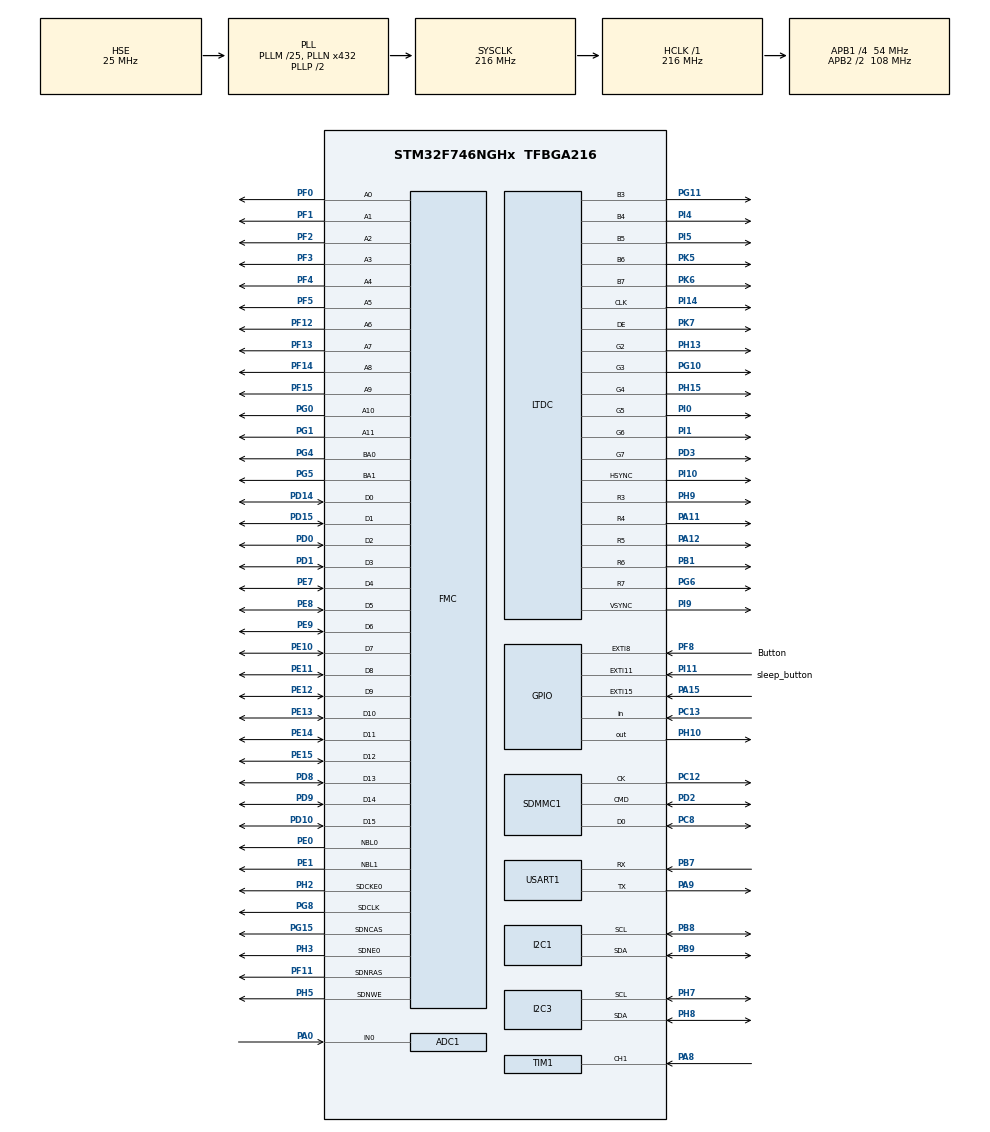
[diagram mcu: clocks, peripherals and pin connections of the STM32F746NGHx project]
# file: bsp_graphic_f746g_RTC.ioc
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ADC1.Channel-0\#ChannelRegularConversion=ADC_CHANNEL_0
ADC1.NbrOfConversionFlag=1
ADC1.Rank-0\#ChannelRegularConversion=1
ADC1.SamplingTime-0\#ChannelRegularConversion=ADC_SAMPLETIME_3CYCLES
ADC1.master=1
CORTEX_M7.ART_ACCELERATOR_ENABLE=1
Dma.Request0=SDMMC1_RX
Dma.Request1=SDMMC1_TX
Dma.SDMMC1_RX.0.Direction=DMA_PERIPH_TO_MEMORY
Dma.SDMMC1_RX.0.FIFOMode=DMA_FIFOMODE_ENABLE
Dma.SDMMC1_RX.0.FIFOThreshold=DMA_FIFO_THRESHOLD_FULL
Dma.SDMMC1_RX.0.Instance=DMA2_Stream3
Dma.SDMMC1_RX.0.MemBurst=DMA_MBURST_INC4
Dma.SDMMC1_RX.0.MemDataAlignment=DMA_MDATAALIGN_WORD
Dma.SDMMC1_RX.0.MemInc=DMA_MINC_ENABLE
Dma.SDMMC1_RX.0.Mode=DMA_PFCTRL
Dma.SDMMC1_RX.0.PeriphBurst=DMA_PBURST_INC4
Dma.SDMMC1_RX.0.PeriphDataAlignment=DMA_PDATAALIGN_WORD
Dma.SDMMC1_RX.0.PeriphInc=DMA_PINC_DISABLE
Dma.SDMMC1_RX.0.Priority=DMA_PRIORITY_LOW
Dma.SDMMC1_TX.1.Direction=DMA_MEMORY_TO_PERIPH
Dma.SDMMC1_TX.1.FIFOMode=DMA_FIFOMODE_ENABLE
Dma.SDMMC1_TX.1.FIFOThreshold=DMA_FIFO_THRESHOLD_FULL
Dma.SDMMC1_TX.1.Instance=DMA2_Stream6
Dma.SDMMC1_TX.1.MemBurst=DMA_MBURST_INC4
Dma.SDMMC1_TX.1.MemDataAlignment=DMA_MDATAALIGN_WORD
Dma.SDMMC1_TX.1.MemInc=DMA_MINC_ENABLE
Dma.SDMMC1_TX.1.Mode=DMA_PFCTRL
Dma.SDMMC1_TX.1.PeriphBurst=DMA_PBURST_INC4
Dma.SDMMC1_TX.1.PeriphDataAlignment=DMA_PDATAALIGN_WORD
Dma.SDMMC1_TX.1.PeriphInc=DMA_PINC_DISABLE
Dma.SDMMC1_TX.1.Priority=DMA_PRIORITY_LOW
FATFS.BSP.number=1
FATFS.USE_DMA_CODE_SD=1
FATFS0.BSP.STBoard=false
FATFS0.BSP.api=Unknown
FATFS0.BSP.instance=PC13
FATFS0.BSP.ip=GPIO
FATFS0.BSP.mode=Input
FATFS0.BSP.name=Detect_SDIO
FATFS0.BSP.solution=PC13
I2C1.Timing=0x20404768
I2C3.Timing=0x20404768
LTDC.ActiveH=272
LTDC.ActiveW=480
LTDC.Alpha_L0=255
LTDC.BlendingFactor1_L0=LTDC_BLENDING_FACTOR1_PAxCA
LTDC.BlendingFactor2_L0=LTDC_BLENDING_FACTOR2_PAxCA
LTDC.HBP=43
LTDC.HFP=8
LTDC.HSync=1
LTDC.ImageHeight_L0=272
LTDC.ImageWidth_L0=480
LTDC.Layers=0
LTDC.PixelFormat_L0=LTDC_PIXEL_FORMAT_RGB565
LTDC.VBP=12
LTDC.VFP=4
LTDC.VSync=10
LTDC.WindowX1_L0=480
LTDC.WindowY1_L0=272
Mcu.Family=STM32F7
Mcu.Name=STM32F746NGHx
Mcu.Package=TFBGA216
NVIC.DMA2_Stream3_IRQn=true\:0\:0\:false\:false\:true\:false\:true\:true
NVIC.DMA2_Stream6_IRQn=true\:0\:0\:false\:false\:true\:false\:true\:true
NVIC.EXTI15_10_IRQn=true\:2\:0\:true\:false\:true\:true\:true\:true
NVIC.EXTI9_5_IRQn=true\:0\:0\:false\:false\:true\:true\:true\:true
NVIC.PriorityGroup=NVIC_PRIORITYGROUP_4
NVIC.RTC_WKUP_IRQn=true\:0\:0\:false\:false\:true\:true\:true\:true
NVIC.SDMMC1_IRQn=true\:0\:0\:false\:false\:true\:true\:true\:true
NVIC.TIM1_CC_IRQn=true\:0\:0\:false\:false\:true\:true\:true\:true
NVIC.TIM2_IRQn=true\:0\:0\:false\:false\:true\:true\:true\:true
NVIC.TIM3_IRQn=true\:0\:0\:false\:false\:true\:true\:true\:true
NVIC.TIM5_IRQn=true\:1\:0\:true\:false\:true\:true\:true\:true
NVIC.TIM6_DAC_IRQn=true\:3\:0\:true\:false\:true\:true\:true\:true
NVIC.TIM7_IRQn=true\:4\:0\:true\:false\:true\:true\:true\:true
NVIC.TIM8_BRK_TIM12_IRQn=true\:0\:0\:false\:false\:true\:true\:true\:true
NVIC.TIM8_UP_TIM13_IRQn=true\:0\:0\:false\:false\:true\:true\:true\:true
PA0/WKUP.Signal=ADCx_IN0
PA11.Mode=RGB565
PA11.Signal=LTDC_R4
PA12.Mode=RGB565
PA12.Signal=LTDC_R5
PA13.Mode=Serial_Wire
PA13.Signal=SYS_JTMS-SWDIO
PA14.Mode=Serial_Wire
PA14.Signal=SYS_JTCK-SWCLK
PA15.GPIO_PuPd=GPIO_PULLUP
PA15.Signal=GPXTI15
PA7.Signal=TIM1_CH1N
PA8.GPIO_PuPd=GPIO_PULLUP
PA8.Signal=S_TIM1_CH1
PA9.Mode=Asynchronous
PA9.Signal=USART1_TX
PB1.Mode=RGB565
PB1.Signal=LTDC_R6
PB7.Mode=Asynchronous
PB7.Signal=USART1_RX
PB8.Mode=I2C
PB8.Signal=I2C1_SCL
PB9.Mode=I2C
PB9.Signal=I2C1_SDA
PC12.Mode=SD_1_bit
PC12.Signal=SDMMC1_CK
PC13.Signal=GPIO_Input
PC14/OSC32_IN.Mode=LSE-External-Oscillator
PC14/OSC32_IN.Signal=RCC_OSC32_IN
PC15/OSC32_OUT.Mode=LSE-External-Oscillator
PC15/OSC32_OUT.Signal=RCC_OSC32_OUT
PC8.Mode=SD_1_bit
PC8.Signal=SDMMC1_D0
PD0.Signal=FMC_D2_DA2
PD1.Signal=FMC_D3_DA3
PD10.Signal=FMC_D15_DA15
PD14.Signal=FMC_D0_DA0
PD15.Signal=FMC_D1_DA1
PD2.Mode=SD_1_bit
PD2.Signal=SDMMC1_CMD
PD3.Mode=RGB565
PD3.Signal=LTDC_G7
PD8.Signal=FMC_D13_DA13
PD9.Signal=FMC_D14_DA14
PE0.Signal=FMC_NBL0
PE1.Signal=FMC_NBL1
PE10.Signal=FMC_D7_DA7
PE11.Signal=FMC_D8_DA8
PE12.Signal=FMC_D9_DA9
PE13.Signal=FMC_D10_DA10
PE14.Signal=FMC_D11_DA11
PE15.Signal=FMC_D12_DA12
PE7.Signal=FMC_D4_DA4
PE8.Signal=FMC_D5_DA5
PE9.Signal=FMC_D6_DA6
PF0.Signal=FMC_A0
PF1.Signal=FMC_A1
PF11.Signal=FMC_SDNRAS
PF12.Signal=FMC_A6
PF13.Signal=FMC_A7
PF14.Signal=FMC_A8
PF15.Signal=FMC_A9
PF2.Signal=FMC_A2
PF3.Signal=FMC_A3
PF4.Signal=FMC_A4
PF5.Signal=FMC_A5
PF8.GPIO_Label=Button
PF8.Signal=GPXTI8
PG0.Signal=FMC_A10
PG1.Signal=FMC_A11
PG10.Mode=RGB565
PG10.Signal=LTDC_G3
PG11.Mode=RGB565
PG11.Signal=LTDC_B3
PG15.Signal=FMC_SDNCAS
PG4.Signal=FMC_A14_BA0
PG5.Signal=FMC_A15_BA1
PG6.Mode=RGB565
PG6.Signal=LTDC_R7
PG8.Signal=FMC_SDCLK
PH0/OSC_IN.Mode=HSE-External-Oscillator
PH0/OSC_IN.Signal=RCC_OSC_IN
PH1/OSC_OUT.Mode=HSE-External-Oscillator
PH1/OSC_OUT.Signal=RCC_OSC_OUT
PH10.Signal=GPIO_Output
PH13.Mode=RGB565
PH13.Signal=LTDC_G2
PH15.Mode=RGB565
PH15.Signal=LTDC_G4
PH2.Mode=SdramChipSelect1_1
PH2.Signal=FMC_SDCKE0
PH3.Mode=SdramChipSelect1_1
PH3.Signal=FMC_SDNE0
PH5.Signal=FMC_SDNWE
PH7.Mode=I2C
PH7.Signal=I2C3_SCL
PH8.Mode=I2C
PH8.Signal=I2C3_SDA
PH9.Mode=RGB565
PH9.Signal=LTDC_R3
PI0.Mode=RGB565
PI0.Signal=LTDC_G5
PI1.Mode=RGB565
PI1.Signal=LTDC_G6
PI10.Mode=RGB565
PI10.Signal=LTDC_HSYNC
PI11.GPIO_Label=sleep_button
PI11.Signal=GPXTI11
PI14.Mode=RGB565
PI14.Signal=LTDC_CLK
PI4.Mode=RGB565
PI4.Signal=LTDC_B4
PI5.Mode=RGB565
PI5.Signal=LTDC_B5
PI9.Mode=RGB565
PI9.Signal=LTDC_VSYNC
PK5.Mode=RGB565
PK5.Signal=LTDC_B6
PK6.Mode=RGB565
PK6.Signal=LTDC_B7
PK7.Mode=RGB565
PK7.Signal=LTDC_DE
ProjectManager.HeapSize=0x400
ProjectManager.StackSize=0x800
ProjectManager.TargetToolchain=STM32CubeIDE
RCC.AHBFreq_Value=216000000
RCC.APB1CLKDivider=RCC_HCLK_DIV4
RCC.APB1Freq_Value=54000000
RCC.APB1TimFreq_Value=108000000
RCC.APB2CLKDivider=RCC_HCLK_DIV2
RCC.APB2Freq_Value=108000000
RCC.APB2TimFreq_Value=216000000
RCC.CortexFreq_Value=216000000
RCC.HCLKFreq_Value=216000000
RCC.HSE_VALUE=25000000
RCC.HSI_VALUE=16000000
RCC.PLLM=25
RCC.PLLN=432
RCC.PLLQ=9
RCC.PLLSAIN=100
RCC.PLLSAIR=4
RCC.PLLSAIRDiv=RCC_PLLSAIDIVR_4
RCC.PLLSourceVirtual=RCC_PLLSOURCE_HSE
RCC.SDMMCClockSelection=RCC_SDMMC1CLKSOURCE_CLK48
RCC.SYSCLKFreq_VALUE=216000000
RCC.SYSCLKSource=RCC_SYSCLKSOURCE_PLLCLK
RCC.USBFreq_Value=48000000
RCC.VCOOutputFreq_Value=432000000
RTC.Alarm-Alarm\ A=RTC_ALARM_A
RTC.Format=RTC_FORMAT_BIN
SH.ADCx_IN0.0=ADC1_IN0,IN0
SH.FMC_A0.0=FMC_A0,12b-sda1
SH.FMC_A1.0=FMC_A1,12b-sda1
SH.FMC_A10.0=FMC_A10,12b-sda1
SH.FMC_A11.0=FMC_A11,12b-sda1
SH.FMC_A14_BA0.0=FMC_BA0,FourSdramBanks1
SH.FMC_A15_BA1.0=FMC_BA1,FourSdramBanks1
SH.FMC_A2.0=FMC_A2,12b-sda1
SH.FMC_A3.0=FMC_A3,12b-sda1
SH.FMC_A4.0=FMC_A4,12b-sda1
SH.FMC_A5.0=FMC_A5,12b-sda1
SH.FMC_A6.0=FMC_A6,12b-sda1
SH.FMC_A7.0=FMC_A7,12b-sda1
SH.FMC_A8.0=FMC_A8,12b-sda1
SH.FMC_A9.0=FMC_A9,12b-sda1
SH.FMC_D0_DA0.0=FMC_D0,sd-16b-d1
SH.FMC_D10_DA10.0=FMC_D10,sd-16b-d1
SH.FMC_D11_DA11.0=FMC_D11,sd-16b-d1
SH.FMC_D12_DA12.0=FMC_D12,sd-16b-d1
SH.FMC_D13_DA13.0=FMC_D13,sd-16b-d1
SH.FMC_D14_DA14.0=FMC_D14,sd-16b-d1
SH.FMC_D15_DA15.0=FMC_D15,sd-16b-d1
SH.FMC_D1_DA1.0=FMC_D1,sd-16b-d1
SH.FMC_D2_DA2.0=FMC_D2,sd-16b-d1
SH.FMC_D3_DA3.0=FMC_D3,sd-16b-d1
SH.FMC_D4_DA4.0=FMC_D4,sd-16b-d1
SH.FMC_D5_DA5.0=FMC_D5,sd-16b-d1
SH.FMC_D6_DA6.0=FMC_D6,sd-16b-d1
SH.FMC_D7_DA7.0=FMC_D7,sd-16b-d1
SH.FMC_D8_DA8.0=FMC_D8,sd-16b-d1
SH.FMC_D9_DA9.0=FMC_D9,sd-16b-d1
SH.FMC_NBL0.0=FMC_NBL0,Sd2ByteEnable1
SH.FMC_NBL1.0=FMC_NBL1,Sd2ByteEnable1
SH.FMC_SDCLK.0=FMC_SDCLK,12b-sda1
SH.FMC_SDNCAS.0=FMC_SDNCAS,12b-sda1
SH.FMC_SDNRAS.0=FMC_SDNRAS,12b-sda1
SH.FMC_SDNWE.0=FMC_SDNWE,12b-sda1
SH.S_TIM1_CH1.0=TIM1_CH1,Input_Capture1_from_TI1
TIM1.Channel-Input_Capture1_from_TI1=TIM_CHANNEL_1
TIM1.Prescaler=99
TIM2.Period=599999
TIM2.Prescaler=10799
TIM3.Period=199
TIM3.Prescaler=9999
TIM5.Period=299999
TIM5.Prescaler=10799
TIM6.Period=8232
TIM6.Prescaler=65535
TIM7.Period=65535
TIM7.Prescaler=3294
TIM8.Prescaler=8231
USART1.VirtualMode-Asynchronous=VM_ASYNC
VP_DMA2D_VS_DMA2D.Mode=DMA2D_Activate
VP_FATFS_VS_SDIO.Mode=SDIO
VP_RTC_VS_RTC_Activate.Mode=RTC_Enabled
VP_RTC_VS_RTC_Alarm_A_Intern.Mode=Alarm A
VP_RTC_VS_RTC_Calendar.Mode=RTC_Calendar
VP_RTC_VS_RTC_WakeUp_intern.Mode=WakeUp
VP_TIM2_VS_ClockSourceITR.Mode=TriggerSource_ITR0
VP_TIM2_VS_ControllerModeReset.Mode=Reset Mode
VP_TIM3_VS_ClockSourceITR.Mode=TriggerSource_ITR0
VP_TIM3_VS_ControllerModeReset.Mode=Reset Mode
VP_TIM5_VS_ClockSourceITR.Mode=TriggerSource_ITR0
VP_TIM5_VS_ControllerModeReset.Mode=Reset Mode
VP_TIM6_VS_ClockSourceINT.Mode=Enable_Timer
VP_TIM7_VS_ClockSourceINT.Mode=Enable_Timer
VP_TIM8_VS_ClockSourceITR.Mode=TriggerSource_ITR0
VP_TIM8_VS_ControllerModeReset.Mode=Reset Mode
board=STM32F746G-DISCO

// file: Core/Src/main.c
/* USER CODE BEGIN Header */
/**
  ******************************************************************************
  * @file           : main.c
  * @brief          : Main program body
  ******************************************************************************
  * @attention
  *
  * Copyright (c) 2023 STMicroelectronics.
  * All rights reserved.
  *
  * This software is licensed under terms that can be found in the LICENSE file
  * in the root directory of this software component.
  * If no LICENSE file comes with this software, it is provided AS-IS.
  *
  ******************************************************************************
  */
/* USER CODE END Header */
#include "main.h"
#include "adc.h"
#include "dma.h"
#include "dma2d.h"
#include "fatfs.h"
#include "i2c.h"
#include "ltdc.h"
#include "rtc.h"
#include "sdmmc.h"
#include "tim.h"
#include "usart.h"
#include "gpio.h"
#include "fmc.h"

/* USER CODE BEGIN Includes */
#include "stdio.h"
#include <string.h>
#include "stm32746g_discovery.h"
#include "stm32746g_discovery_sdram.h"
#include "stm32746g_discovery_lcd.h"
#include "stm32746g_discovery_ts.h"

#include "Interface.h"
#include "Nucleo_HumTemp_I2C.h"
#include "Nucleo_Pression_I2C.h"
#include "Rain_Measure_Sparkfun.h"
#include "SD_card.h"
#include "Wind_Dir_Sparkfun.h"
#include "Wind_Speed_Sparkfun.h"
/*#include "Rain_Measure_Sparkfun.h"
#include "Wind_Dir_Sparkfun.h"
#include "Wind_Speed_Sparkfun.h"
*/
/* USER CODE END Includes */

/* USER CODE BEGIN PV */

//Taille de l'écran

volatile TS_StateTypeDef  TS_State;
volatile uint16_t x, y;
int needRedraw=1;
int debounce = 0; // Debounce flag

// Variable pour suivre l'état du système
extern uint8_t minute_flag;  // Flag pour indiquer que 1 minute est écoulée
uint8_t flag=0;
volatile uint8_t flag_meteo=0;
extern int graph_open_flag;

uint8_t flag_ext_button=0;
uint8_t time_IRQ_acquisition;
uint8_t flag_IRQ_sleep=0;

extern uint32_t rainCount;
extern uint8_t flagRain;

/* USER CODE END PV */

void SystemClock_Config(void);
/* USER CODE BEGIN PFP */

#ifdef __GNUC__
/* With GCC/RAISONANCE, small printf (option LD Linker->Libraries->Small printf
set to 'Yes') calls __io_putchar() */
#define PUTCHAR_PROTOTYPE int __io_putchar(int ch)
#else
#define PUTCHAR_PROTOTYPE int fputc(int ch, FILE *f)
#endif /* __GNUC__ */

void TouchTimer_Init(void);

/**
 * @brief Récupère la date formatée depuis la RTC
 * @param dateStr: buffer pour stocker la chaîne formatée
 */
void getRTCDateStr(char* dateStr) {
    // Lecture de l'heure (nécessaire avant la date)
    HAL_RTC_GetTime(&hrtc, &sTime, RTC_FORMAT_BIN);
    // Lecture de la date
    HAL_RTC_GetDate(&hrtc, &sDate, RTC_FORMAT_BIN);

    // Format: "Jour JJ/MM/AAAA"
    sprintf(dateStr, "%02d/%02d/20%02d",
            sDate.Date,
            sDate.Month,
            sDate.Year);
}

/**
 * @brief Récupère l'heure formatée depuis la RTC
 * @param timeStr: buffer pour stocker la chaîne formatée
 */

/* USER CODE END PFP */

int main(void)
{

  /* MCU Configuration--------------------------------------------------------*/

  /* Reset of all peripherals, Initializes the Flash interface and the Systick. */
  HAL_Init();

  /* Configure the system clock */
  SystemClock_Config();

  /* Initialize all configured peripherals */
  MX_GPIO_Init();
  MX_DMA_Init();
  MX_DMA2D_Init();
  MX_FMC_Init();
  MX_LTDC_Init();
  MX_USART1_UART_Init();
  MX_I2C3_Init();
  MX_TIM3_Init();
  MX_RTC_Init();
  MX_SDMMC1_SD_Init();
  MX_I2C1_Init();
  MX_FATFS_Init();
  MX_ADC1_Init();
  MX_TIM1_Init();
  MX_TIM6_Init();
  MX_TIM7_Init();
  MX_TIM5_Init();
  MX_TIM8_Init();
  MX_TIM2_Init();
  /* USER CODE BEGIN 2 */
  BSP_LCD_Init();
  BSP_LCD_LayerDefaultInit(LTDC_ACTIVE_LAYER, SDRAM_DEVICE_ADDR);
  BSP_LCD_SetLayerVisible(LTDC_ACTIVE_LAYER, ENABLE);
  BSP_LCD_SetFont(&LCD_DEFAULT_FONT);
  BSP_LCD_SelectLayer(LTDC_ACTIVE_LAYER);
  BSP_LCD_Clear(LCD_COLOR_WHITE);
  BSP_LCD_SetBackColor(LCD_COLOR_WHITE);
  BSP_LCD_SetTextColor(LCD_COLOR_BLACK);

  init_HumTemp();
  init_Pression();
  //BSP_TS_Init(BSP_LCD_GetXSize(), BSP_LCD_GetYSize());
  TouchTimer_Init();
  HAL_TIM_IC_Start_IT(&htim1, TIM_CHANNEL_1);
  HAL_TIM_Base_Start_IT(&htim7);

  __HAL_TIM_SET_COUNTER(&htim5, 0);           // Réinitialise le compteur à 0
  __HAL_TIM_CLEAR_FLAG(&htim5, TIM_FLAG_UPDATE); // Efface le drapeau d'interruption
  HAL_TIM_Base_Start_IT(&htim5);

  __HAL_TIM_SET_COUNTER(&htim8, 0);           // Réinitialise le compteur à 0
  __HAL_TIM_CLEAR_FLAG(&htim8, TIM_FLAG_UPDATE); // Efface le drapeau d'interruption
  HAL_TIM_Base_Start_IT(&htim8);

  __HAL_TIM_SET_COUNTER(&htim2, 0);           // Réinitialise le compteur à 0
  __HAL_TIM_CLEAR_FLAG(&htim2, TIM_FLAG_UPDATE); // Efface le drapeau d'interruption
  HAL_TIM_Base_Start_IT(&htim2);

  init_sd_logging();

  /* USER CODE END 2 */

  /* Infinite loop */
  while (1) {

    /* USER CODE BEGIN 3 */
         //machine d' etat de l'inteface graphique
         if (needRedraw) {
             switch (flag) {
                 case 0:
                     drawMenuPage();
                     needRedraw = 0; // Reset the redraw flag
                     break;

                 case 1:
                	 drawTempHumidRainPage();
                     needRedraw = 0; // Reset the redraw flag
                     break;

                 case 2:
                      drawWindDirPressurePage();
                      needRedraw = 0; // Reset the redraw flag
                      break;

                 case 3:
                      drawSettingsPage();
                      needRedraw = 0; // Reset the redraw flag
                      break;

                  case 4:
                      drawCreditsPage();
                      needRedraw = 0; // Reset the redraw flag
                      break;

                  case 5:
                	  valeur_graph_TempH();
                      //needRedraw = 0; // Reset the redraw flag
                      break;

                  case 6:
                	  value_humidity_graph();
                      //needRedraw = 0; // Reset the redraw flag
                      break;

                  case 7:
                	  //drawTempHumGraphPage();
                      needRedraw = 0; // Reset the redraw flag
                      break;

                  case 8:
                	  manage_pressure_graph();
                      //needRedraw = 0; // Reset the redraw flag
                      break;

                  case 9:
                	  //drawRainPressGraphPage();
                      needRedraw = 0; // Reset the redraw flag
                      break;
                }
         }

         //affichage des valeurs toutes les 5 secondes
         else if(time_IRQ_acquisition)
         {
			 if(flag==1){
					 valeur_TempH();
					 valeur_Hum();
					 if(flag_meteo==0){
						 Draw_Rain_Measure_Value();
					 }
				 }

  	  	  	 else if(flag==2){
  	  	  		 valeur_Pression();
  	  	  		 if(flag_meteo==0){
					 Wind_Dir_Value();
					 Wind_Speed_Value();
  	  	  		 }
  			 }

			 time_IRQ_acquisition=0;
         }

		 //condition de mise en sommeil et de réveil
		 else if (flag_IRQ_sleep == 1) {
			BSP_LCD_DisplayOff();
			printf("Entrée en sommeil\r\n");

			// Entrer en mode STOP
			HAL_PWR_EnterSTOPMode(PWR_MAINREGULATOR_ON, PWR_SLEEPENTRY_WFI);
			//HAL_SuspendTick() et HAL_ResumeTick() non utilisé pour la RTC;

			//reactivation et redessinage de l'interface
			SystemClock_Config(); // Reconfigure les horloges
			BSP_LCD_Init();
			BSP_LCD_DisplayOn();  // Rallume l'écran
			BSP_LCD_SetFont(&Font16); // Police de caractères pour l'affichage

			needRedraw = 1;

			//redémarrage du compteur
			HAL_TIM_Base_Stop_IT(&htim5);  // Arrêter le timer en mode veille
			__HAL_TIM_SET_COUNTER(&htim5, 0);  // Réinitialiser le compteur du timer
			__HAL_TIM_CLEAR_FLAG(&htim5, TIM_FLAG_UPDATE); // Efface le drapeau d'interruption
			HAL_TIM_Base_Start_IT(&htim5);  // Redémarrer le timer
			printf("Réveil de l'écran\r\n");

  	  	 }

         //changement d'état par interruption sur bouton du touch screen
         if (TS_State.touchDetected && !debounce) {

        	 debounce=1;
			   //hum Temp Rain button
			  if (flag == 0 && x > 40 && x < 220 && y > 60 && y < 220) {
				  flag = 1;
				  needRedraw = 1; // Set the redraw flag

			  //return menu button
			  } else if ((flag == 1 || flag == 2 || flag == 3 || flag == 4) && x > 10 && x < 40 && y > 10 && y < 40) {
				  flag = 0;
				  needRedraw = 1; // Set the redraw flag

			   //wind dir pressure button
			  } else if (flag == 0 && x > 260 && x < 440 && y > 60 && y < 220) {
				  flag = 2;
				  needRedraw = 1; // Set the redraw flag

			   //setting button
			  } else if (flag == 0 && x > 438 && x < 480 && y > 235 && y < 272) {
				  flag = 3;
				  needRedraw = 1; // Set the redraw flag

			  //credits button
			  } else if (flag == 0 && x > 18 && x < 58 && y > 235 && y < 272) {
				  flag = 4;
				  needRedraw = 1; // Set the redraw flag

			  //Temperature graph
			  } else if (flag == 1 && x > 40 && x < 160 && y > 80 && y < 200) {
				  flag = 5;
				  needRedraw = 1; // Set the redraw flag

			  //humidity graph
         	  } else if (flag == 1 && x > 180 && x < 300 && y > 80 && y < 200){
         		 flag = 6;
         		 needRedraw = 1; // Set the redraw flag

         	  //Rain graph
         	  } /*else if (flag == 1 && x > 320 && x < 440 && y > 80 && y < 200){
          		 flag = 7;
          		 needRedraw = 1; // Set the redraw flag

          	  //Pressure graph
         	  }*/ else if (flag == 2 && x > 320 && x < 440 && y > 80 && y < 200){
				 flag = 8;
				 needRedraw = 1; // Set the redraw flag

			  //Wind Graph
			  }/*else if (flag == 2 && x > 40 && x < 160 && y > 80 && y < 200){
				 flag = 9;
				 needRedraw = 1; // Set the redraw flag

			  //return data page 1 button
			  }*/ else if ((flag == 5 || flag == 6 || flag == 7) && x > 10 && x < 40 && y > 10 && y < 40) {
				  flag = 1;
				  needRedraw = 1; // Set the redraw flag

			  //return data page 2 button
			  } else if ((flag == 8 || flag == 9) && x > 10 && x < 40 && y > 10 && y < 40) {
				  flag = 2;
				  needRedraw = 1; // Set the redraw flag

			  } else if (flag == 3) {
				      const uint16_t col1 = 150;
				      const uint16_t col2 = col1 + 90;
				      const uint16_t col3 = col2 + 90;
				      const uint16_t buttonSize = 30;

				      // Bouton retour
				      if (x > 10 && x < 40 && y > 10 && y < 40) {
				          flag = 0;
				          needRedraw = 1;
				      }
				      // === Boutons Date ===
				      // Jour +
				      else if (x >= col1 && x <= col1 + buttonSize && y >= 40 && y <= 70) {
				          HAL_RTC_GetTime(&hrtc, &sTime, RTC_FORMAT_BIN);
				          HAL_RTC_GetDate(&hrtc, &sDate, RTC_FORMAT_BIN);
				          sDate.Date = (sDate.Date % 31) + 1;
				          needRedraw = 1;
				      }
				      // Jour -
				      else if (x >= col1 && x <= col1 + buttonSize && y >= 105 && y <= 135) {

				          HAL_RTC_GetTime(&hrtc, &sTime, RTC_FORMAT_BIN);
				          HAL_RTC_GetDate(&hrtc, &sDate, RTC_FORMAT_BIN);
				          sDate.Date = (sDate.Date > 1) ? sDate.Date - 1 : 31;
				          needRedraw = 1;
				      }
				      // Mois +
				      else if (x >= col2 && x <= col2 + buttonSize && y >= 40 && y <= 70) {
				          HAL_RTC_GetTime(&hrtc, &sTime, RTC_FORMAT_BIN);
				          HAL_RTC_GetDate(&hrtc, &sDate, RTC_FORMAT_BIN);
				          sDate.Month = (sDate.Month % 12) + 1;
				          needRedraw = 1;
				      }
				      // Mois -
				      else if (x >= col2 && x <= col2 + buttonSize && y >= 105 && y <= 135) {

				          HAL_RTC_GetTime(&hrtc, &sTime, RTC_FORMAT_BIN);
				          HAL_RTC_GetDate(&hrtc, &sDate, RTC_FORMAT_BIN);
				          sDate.Month = (sDate.Month > 1) ? sDate.Month - 1 : 12;
				          needRedraw = 1;
				      }
				      // === Boutons Heure ===
				      // Heures +
				      else if (x >= col1 && x <= col1 + buttonSize && y >= 140 && y <= 170) {

				          HAL_RTC_GetTime(&hrtc, &sTime, RTC_FORMAT_BIN);
				          HAL_RTC_GetDate(&hrtc, &sDate, RTC_FORMAT_BIN);
				          sTime.Hours = (sTime.Hours + 1) % 24;
				          needRedraw = 1;
				      }
				      // Heures -
				      else if (x >= col1 && x <= col1 + buttonSize && y >= 200 && y <= 230) {

				          HAL_RTC_GetTime(&hrtc, &sTime, RTC_FORMAT_BIN);
				          HAL_RTC_GetDate(&hrtc, &sDate, RTC_FORMAT_BIN);
				          sTime.Hours = (sTime.Hours > 0) ? sTime.Hours - 1 : 23;
				          needRedraw = 1;
				      }
				      // Minutes +
				      else if (x >= col2 && x <= col2 + buttonSize && y >= 140 && y <= 170) {

				          HAL_RTC_GetTime(&hrtc, &sTime, RTC_FORMAT_BIN);
				          HAL_RTC_GetDate(&hrtc, &sDate, RTC_FORMAT_BIN);
				          sTime.Minutes = (sTime.Minutes + 1) % 60;
				          needRedraw = 1;
				      }
				      // Minutes -
				      else if (x >= col2 && x <= col2 + buttonSize && y >= 200 && y <= 230) {

				          HAL_RTC_GetTime(&hrtc, &sTime, RTC_FORMAT_BIN);
				          HAL_RTC_GetDate(&hrtc, &sDate, RTC_FORMAT_BIN);
				          sTime.Minutes = (sTime.Minutes > 0) ? sTime.Minutes - 1 : 59;
				          needRedraw = 1;
				      }
				      // Année +
				      else if (x >= col3 && x <= col3 + buttonSize && y >= 40 && y <= 70) {
				          HAL_RTC_GetTime(&hrtc, &sTime, RTC_FORMAT_BIN);
				          HAL_RTC_GetDate(&hrtc, &sDate, RTC_FORMAT_BIN);
				          if(sDate.Year < 99) {  // Limite pour format BCD
				              sDate.Year++;
				              HAL_RTC_SetDate(&hrtc, &sDate, RTC_FORMAT_BIN);
				              needRedraw = 1;
				          }
				      }
				      // Année -
				      else if (x >= col3 && x <= col3 + buttonSize && y >= 105 && y <= 135) {

				          HAL_RTC_GetTime(&hrtc, &sTime, RTC_FORMAT_BIN);
				          HAL_RTC_GetDate(&hrtc, &sDate, RTC_FORMAT_BIN);
				          if(sDate.Year > 0) {
				              sDate.Year--;
				              HAL_RTC_SetDate(&hrtc, &sDate, RTC_FORMAT_BIN);
				              needRedraw = 1;
				          }
				      }
				      // Bouton Valider
				      else if (x >= 340 && x <= 440 && y >= 220 && y <= 250) {
				          HAL_RTC_GetTime(&hrtc, &sTime, RTC_FORMAT_BIN);
				          HAL_RTC_GetDate(&hrtc, &sDate, RTC_FORMAT_BIN);
				          // Mise à jour de la date et de l'heure
				          HAL_RTC_SetTime(&hrtc, &sTime, RTC_FORMAT_BIN);
				          HAL_RTC_SetDate(&hrtc, &sDate, RTC_FORMAT_BIN);
				          flag = 0;
				          needRedraw = 1;
				      }

				      // Si une valeur a été modifiée, on met à jour la RTC
				      if (needRedraw) {
				          if (flag == 3) {  // Si on est toujours sur la page de réglage
				              HAL_RTC_SetTime(&hrtc, &sTime, RTC_FORMAT_BIN);
				              HAL_RTC_SetDate(&hrtc, &sDate, RTC_FORMAT_BIN);
				          }
				      }
				  //remise à 0 du timer 5 si l'écran est touché (Mise en sommeil).

				  }
			  	  HAL_TIM_Base_Stop(&htim5);
			  	  __HAL_TIM_SET_COUNTER(&htim5, 0);
			  	  HAL_TIM_Base_Start(&htim5);

		  } else if (!TS_State.touchDetected) {
			  debounce = 0; // Reset debounce flag when touch is released
		  }
		 //HAL_Delay(50); // Delay to reduce loop speed and debounce effect
  }
  /* USER CODE END 3 */
}

void SystemClock_Config(void)
{
  RCC_OscInitTypeDef RCC_OscInitStruct = {0};
  RCC_ClkInitTypeDef RCC_ClkInitStruct = {0};

  /** Configure LSE Drive Capability
  */
  HAL_PWR_EnableBkUpAccess();

  /** Configure the main internal regulator output voltage
  */
  __HAL_RCC_PWR_CLK_ENABLE();
  __HAL_PWR_VOLTAGESCALING_CONFIG(PWR_REGULATOR_VOLTAGE_SCALE1);

  /** Initializes the RCC Oscillators according to the specified parameters
  * in the RCC_OscInitTypeDef structure.
  */
  RCC_OscInitStruct.OscillatorType = RCC_OSCILLATORTYPE_LSI|RCC_OSCILLATORTYPE_HSE;
  RCC_OscInitStruct.HSEState = RCC_HSE_ON;
  RCC_OscInitStruct.LSIState = RCC_LSI_ON;
  RCC_OscInitStruct.PLL.PLLState = RCC_PLL_ON;
  RCC_OscInitStruct.PLL.PLLSource = RCC_PLLSOURCE_HSE;
  RCC_OscInitStruct.PLL.PLLM = 25;
  RCC_OscInitStruct.PLL.PLLN = 432;
  RCC_OscInitStruct.PLL.PLLP = RCC_PLLP_DIV2;
  RCC_OscInitStruct.PLL.PLLQ = 9;
  if (HAL_RCC_OscConfig(&RCC_OscInitStruct) != HAL_OK)
  {
    Error_Handler();
  }

  /** Activate the Over-Drive mode
  */
  if (HAL_PWREx_EnableOverDrive() != HAL_OK)
  {
    Error_Handler();
  }

  /** Initializes the CPU, AHB and APB buses clocks
  */
  RCC_ClkInitStruct.ClockType = RCC_CLOCKTYPE_HCLK|RCC_CLOCKTYPE_SYSCLK
                              |RCC_CLOCKTYPE_PCLK1|RCC_CLOCKTYPE_PCLK2;
  RCC_ClkInitStruct.SYSCLKSource = RCC_SYSCLKSOURCE_PLLCLK;
  RCC_ClkInitStruct.AHBCLKDivider = RCC_SYSCLK_DIV1;
  RCC_ClkInitStruct.APB1CLKDivider = RCC_HCLK_DIV4;
  RCC_ClkInitStruct.APB2CLKDivider = RCC_HCLK_DIV2;

  if (HAL_RCC_ClockConfig(&RCC_ClkInitStruct, FLASH_LATENCY_7) != HAL_OK)
  {
    Error_Handler();
  }
}

/* USER CODE BEGIN 4 */
void TouchTimer_Init() {
    BSP_TS_Init(BSP_LCD_GetXSize(), BSP_LCD_GetYSize());

    if (HAL_TIM_Base_Init(&htim3) != HAL_OK) {
        while (1);
    }
    if (HAL_TIM_Base_Start_IT(&htim3) != HAL_OK) {
        while (1);
    }
}

void PollTouchScreen(void)
{
	static TS_StateTypeDef prev_state;    /* Previous touch state from the touch sensor used from BSP package */
	TS_StateTypeDef ts;                   /* Actual touch state from the touch sensor used from BSP package */
	BSP_TS_GetState(&ts);                 /* Read the touch state from touch sensor (BSP API)*/
	TS_State.touchDetected = ts.touchDetected;  /* Store pressed state */

	/* Check if the touch is pressed */
	if ((prev_state.touchDetected != ts.touchDetected))
	{
		prev_state.touchDetected = ts.touchDetected;
		/* Check touch variations */
		if ((ts.touchX[0] != 0) && (ts.touchY[0] != 0))
		{
		  prev_state.touchX[0] = ts.touchX[0];
		  prev_state.touchY[0] = ts.touchY[0];
		}
		x = prev_state.touchX[0];
		y = prev_state.touchY[0];
	}
}

//interruption timer
void HAL_TIM_PeriodElapsedCallback(TIM_HandleTypeDef *htim)
{
  /* USER CODE BEGIN Callback 0 */

  /* USER CODE END Callback 0 */

  /* USER CODE BEGIN Callback 1 */
  //routine de l'écran tactile
  if (htim->Instance == TIM3)
  {
	  PollTouchScreen();
 	  date_Heure();

  }
  //routine d'interruption pour un arret à 1 minute (Annemometre)
  else if (htim->Instance == TIM6) {
	  // Timer pour mesurer la valeur moyenne du vent
	  minute_flag = 1; // Activer le flag indiquant la fin de 1 minute (5s pour le test)
	  printf("Minute flag set!\r\n"); // Pour vérifier que l'interruption est déclenchée
  }

  //capteur
  else if(htim->Instance == TIM8) {
  	  // Timer valeur toute les 5s
	  time_IRQ_acquisition=1; // Activer le flag indiquant la fin de 1 minute
    }

  else if(htim->Instance == TIM7) {
	  	//écriture des valeurs sur la carte SD;
          printf("Tentative d'enregistrement...\n");  // Debug
          log_weather_data();
    }

  else if(htim->Instance == TIM5) {
	  // Timer 30 seconde atteint(mise en veille)
	  flag_IRQ_sleep=1; // Activer le flag indiquant la fin de 1 minute
  }

  else if(htim->Instance == TIM2) {
  	  // Timer si 1 minute atteint
  	  flag_meteo=1; // Activer le flag indiquant la fin de 1 minute
  }
  /* USER CODE END Callback 1 */
}

//interruption GPIO
void HAL_GPIO_EXTI_Callback(uint16_t GPIO_Pin) {
    UNUSED(GPIO_Pin);

    if(GPIO_Pin == GPIO_PIN_15){
    	  rainCount++;
    	  flagRain=1;
    }

    else if (GPIO_Pin == sleep_button_Pin) {
          flag_ext_button = 1;
    	  flag_IRQ_sleep=0;
    }
}

PUTCHAR_PROTOTYPE
{
/* Place your implementation of fputc here */
/* e.g. write a character to the USART1 and Loop until the end of transmission */
HAL_UART_Transmit(&huart1, (uint8_t *)&ch, 1, 100);
return ch;
}

/* USER CODE END 4 */

void Error_Handler(void)
{
  __disable_irq();
  while (1)
  {
  }
}
